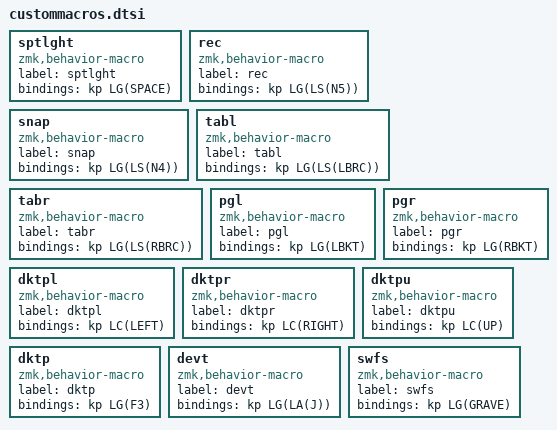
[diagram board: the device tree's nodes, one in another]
  sptlght: sptlght {
    compatible = "zmk,behavior-macro";
    label = "sptlght";
    #binding-cells = <0>;
    bindings = <&kp LG(SPACE)>;
  };

  rec: rec {
    compatible = "zmk,behavior-macro";
    label = "rec";
    #binding-cells = <0>;
    bindings = <&kp LG(LS(N5))>;
  };

  snap: snap {
    compatible = "zmk,behavior-macro";
    label = "snap";
    #binding-cells = <0>;
    bindings = <&kp LG(LS(N4))>;
  };

  tabl: tabl {
    compatible = "zmk,behavior-macro";
    label = "tabl";
    #binding-cells = <0>;
    bindings = <&kp LG(LS(LBRC))>;
  };

  tabr: tabr {
    compatible = "zmk,behavior-macro";
    label = "tabr";
    #binding-cells = <0>;
    bindings = <&kp LG(LS(RBRC))>;
  };

  pgl: pgl {
    compatible = "zmk,behavior-macro";
    label = "pgl";
    #binding-cells = <0>;
    bindings = <&kp LG(LBKT)>;
  };

  pgr: pgr {
    compatible = "zmk,behavior-macro";
    label = "pgr";
    #binding-cells = <0>;
    bindings = <&kp LG(RBKT)>;
  };

  dktpl: dktpl {
    compatible = "zmk,behavior-macro";
    label = "dktpl";
    #binding-cells = <0>;
    bindings = <&kp LC(LEFT)>;
  };

  dktpr: dktpr {
    compatible = "zmk,behavior-macro";
    label = "dktpr";
    #binding-cells = <0>;
    bindings = <&kp LC(RIGHT)>;
  };

  dktpu: dktpu {
    compatible = "zmk,behavior-macro";
    label = "dktpu";
    #binding-cells = <0>;
    bindings = <&kp LC(UP)>;
  };

  dktp: dktp {
    compatible = "zmk,behavior-macro";
    label = "dktp";
    #binding-cells = <0>;
    bindings = <&kp LG(F3)>;
  };

  devt: devt {
    compatible = "zmk,behavior-macro";
    label = "devt";
    #binding-cells = <0>;
    bindings = <&kp LG(LA(J))>;
  };

  swfs: swfs {
    compatible = "zmk,behavior-macro";
    label = "swfs";
    #binding-cells = <0>;
    bindings = <&kp LG(GRAVE)>;
  };
